# STM32L152 register map
File version: 1.2
CPU: CM3 r1p1, little endian, no MPU, no FPU, 4 interrupt priority bits
Registers are 32-bit, read-write, reset 0x0 unless marked. A register's access mark holds for its fields unless they carry their own. Offsets are from the block's base; [hi:lo] are bit positions; {n}, {i} and the like mark numbered series.

## RCC — Reset and clock control
Base 0x40023800
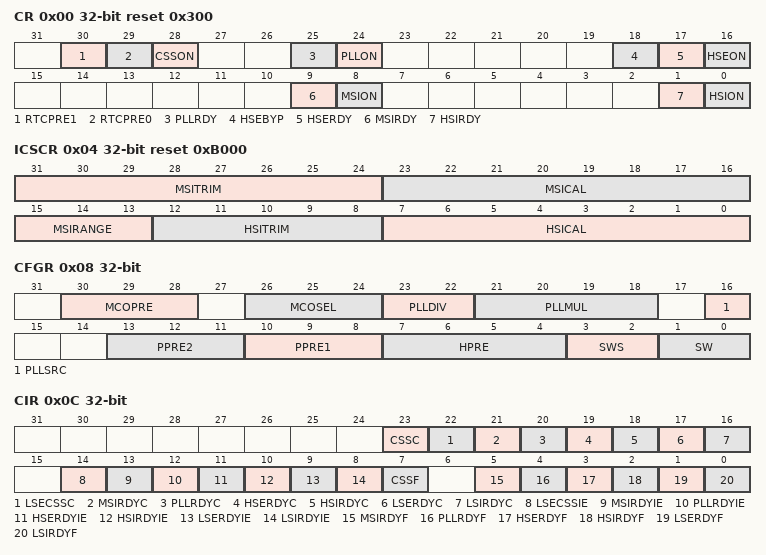
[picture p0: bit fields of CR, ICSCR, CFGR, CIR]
0x00 CR access per field reset 0x300 — Clock control register
  [30] RTCPRE1 rw — TC/LCD prescaler
  [29] RTCPRE0 rw
  [28] CSSON rw — Clock security system enable
  [25] PLLRDY ro — PLL clock ready flag
  [24] PLLON rw — PLL enable
  [18] HSEBYP rw — HSE clock bypass
  [17] HSERDY ro — HSE clock ready flag
  [16] HSEON rw — HSE clock enable
  [9] MSIRDY ro — MSI clock ready flag
  [8] MSION rw — MSI clock enable
  [1] HSIRDY ro — Internal high-speed clock ready flag
  [0] HSION rw — Internal high-speed clock enable
0x04 ICSCR access per field reset 0xB000 — Internal clock sources calibration register
  [31:24] MSITRIM rw — MSI clock trimming
  [23:16] MSICAL ro — MSI clock calibration
  [15:13] MSIRANGE rw — MSI clock ranges
  [12:8] HSITRIM rw — High speed internal clock trimming
  [7:0] HSICAL ro — nternal high speed clock calibration
0x08 CFGR access per field — Clock configuration register
  [30:28] MCOPRE rw — Microcontroller clock output prescaler
  [26:24] MCOSEL rw — Microcontroller clock output selection
  [23:22] PLLDIV rw — PLL output division
  [21:18] PLLMUL rw — PLL multiplication factor
  [16] PLLSRC rw — PLL entry clock source
  [13:11] PPRE2 rw — APB high-speed prescaler (APB2)
  [10:8] PPRE1 rw — APB low-speed prescaler (APB1)
  [7:4] HPRE rw — AHB prescaler
  [3:2] SWS ro — System clock switch status
  [1:0] SW rw — System clock switch
0x0C CIR access per field — Clock interrupt register
  [23] CSSC wo — Clock security system interrupt clear
  [22] LSECSSC wo — LSE CSS interrupt clear
  [21] MSIRDYC wo — MSI ready interrupt clear
  [20] PLLRDYC wo — PLL ready interrupt clear
  [19] HSERDYC wo — HSE ready interrupt clear
  [18] HSIRDYC wo — HSI ready interrupt clear
  [17] LSERDYC wo — LSE ready interrupt clear
  [16] LSIRDYC wo — LSI ready interrupt clear
  [14] LSECSSIE rw — LSE CSS interrupt enable
  [13] MSIRDYIE rw — MSI ready interrupt enable
  [12] PLLRDYIE rw — PLL ready interrupt enable
  [11] HSERDYIE rw — HSE ready interrupt enable
  [10] HSIRDYIE rw — HSI ready interrupt enable
  [9] LSERDYIE rw — LSE ready interrupt enable
  [8] LSIRDYIE rw — LSI ready interrupt enable
  [7] CSSF ro — Clock security system interrupt flag
  [5] MSIRDYF ro — MSI ready interrupt flag
  [4] PLLRDYF ro — PLL ready interrupt flag
  [3] HSERDYF ro — HSE ready interrupt flag
  [2] HSIRDYF ro — HSI ready interrupt flag
  [1] LSERDYF ro — LSE ready interrupt flag
  [0] LSIRDYF ro — LSI ready interrupt flag
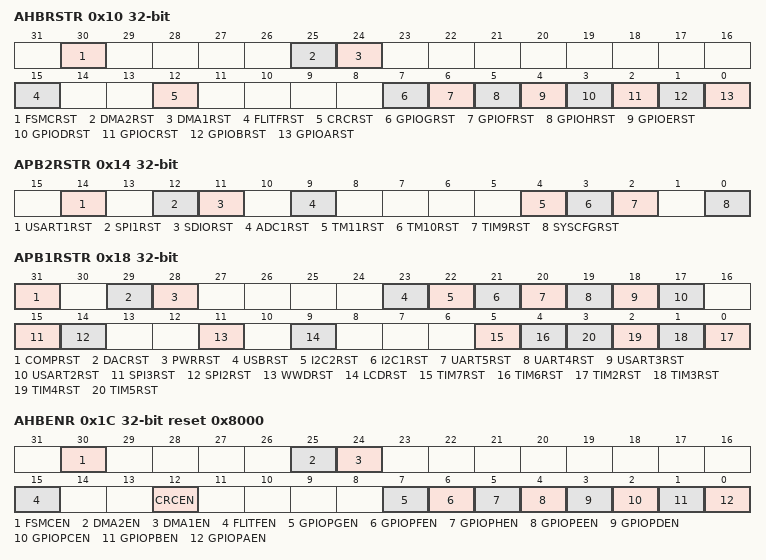
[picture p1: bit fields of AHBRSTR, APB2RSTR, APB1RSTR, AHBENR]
0x10 AHBRSTR — AHB peripheral reset register
  [30] FSMCRST — FSMC reset
  [25] DMA2RST — DMA2 reset
  [24] DMA1RST — DMA1 reset
  [15] FLITFRST — FLITF reset
  [12] CRCRST — CRC reset
  [7] GPIOGRST — IO port G reset
  [6] GPIOFRST — IO port F reset
  [5] GPIOHRST — IO port H reset
  [4] GPIOERST — IO port E reset
  [3] GPIODRST — IO port D reset
  [2] GPIOCRST — IO port C reset
  [1] GPIOBRST — IO port B reset
  [0] GPIOARST — IO port A reset
0x14 APB2RSTR — APB2 peripheral reset register
  [14] USART1RST, [12] SPI1RST, [11] SDIORST, [9] ADC1RST, [4] TM11RST, [3] TM10RST, [2] TIM9RST, [0] SYSCFGRST
0x18 APB1RSTR — APB1 peripheral reset register
  [31] COMPRST — COMP interface reset
  [29] DACRST — DAC interface reset
  [28] PWRRST — Power interface reset
  [23] USBRST — USB reset
  [22] I2C2RST — I2C 2 reset
  [21] I2C1RST — I2C 1 reset
  [20] UART5RST — UART 5 reset
  [19] UART4RST — UART 4 reset
  [18] USART3RST — USART 3 reset
  [17] USART2RST — USART 2 reset
  [15] SPI3RST — SPI 3 reset
  [14] SPI2RST — SPI 2 reset
  [11] WWDRST — Window watchdog reset
  [9] LCDRST — LCD reset
  [5] TIM7RST — Timer 7 reset
  [4] TIM6RST — Timer 6reset
  [n-2] TIM{n}RST (n=2..5) — Timer {n} reset
0x1C AHBENR reset 0x8000 — AHB peripheral clock enable register
  [30] FSMCEN
  [25] DMA2EN — DMA2 clock enable
  [24] DMA1EN — DMA1 clock enable
  [15] FLITFEN — FLITF clock enable
  [12] CRCEN — CRC clock enable
  [7] GPIOPGEN — IO port G clock enable
  [6] GPIOPFEN — IO port F clock enable
  [5] GPIOPHEN — IO port H clock enable
  [4] GPIOPEEN — IO port E clock enable
  [3] GPIOPDEN — IO port D clock enable
  [2] GPIOPCEN — IO port C clock enable
  [1] GPIOPBEN — IO port B clock enable
  [0] GPIOPAEN — IO port A clock enable
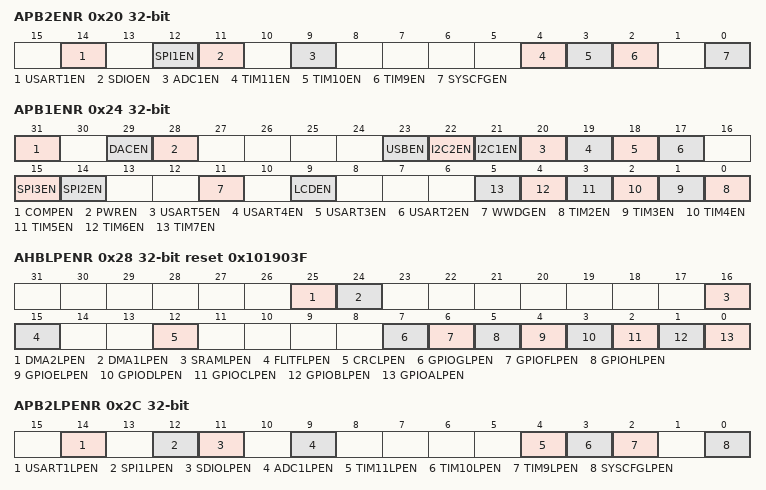
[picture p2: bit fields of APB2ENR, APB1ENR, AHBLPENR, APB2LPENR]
0x20 APB2ENR — APB2 peripheral clock enable register
  [14] USART1EN — USART1 clock enable
  [12] SPI1EN — SPI 1 clock enable
  [11] SDIOEN — SDIO clock enable
  [9] ADC1EN — ADC1 interface clock enable
  [4] TIM11EN — TIM11 timer clock enable
  [3] TIM10EN — TIM10 timer clock enable
  [2] TIM9EN — TIM9 timer clock enable
  [0] SYSCFGEN — System configuration controller clock enable
0x24 APB1ENR — APB1 peripheral clock enable register
  [31] COMPEN — COMP interface clock enable
  [29] DACEN — DAC interface clock enable
  [28] PWREN — Power interface clock enable
  [23] USBEN — USB clock enable
  [22] I2C2EN — I2C 2 clock enable
  [21] I2C1EN — I2C 1 clock enable
  [20] USART5EN — UART 5 clock enable
  [19] USART4EN — UART 4 clock enable
  [18] USART3EN — USART 3 clock enable
  [17] USART2EN — USART 2 clock enable
  [15] SPI3EN — SPI 3 clock enable
  [14] SPI2EN — SPI 2 clock enable
  [11] WWDGEN — Window watchdog clock enable
  [9] LCDEN — LCD clock enable
  [n-2] TIM{n}EN (n=2..7) — Timer {n} clock enable
0x28 AHBLPENR reset 0x101903F — AHB peripheral clock enable in low power mode register
  [25] DMA2LPEN — DMA2 clock enable during Sleep mode
  [24] DMA1LPEN — DMA1 clock enable during Sleep mode
  [16] SRAMLPEN — SRAM clock enable during Sleep mode
  [15] FLITFLPEN — FLITF clock enable during Sleep mode
  [12] CRCLPEN — CRC clock enable during Sleep mode
  [7] GPIOGLPEN — IO port G clock enable during Sleep mode
  [6] GPIOFLPEN — IO port F clock enable during Sleep mode
  [5] GPIOHLPEN — IO port H clock enable during Sleep mode
  [4] GPIOELPEN — IO port E clock enable during Sleep mode
  [3] GPIODLPEN — IO port D clock enable during Sleep mode
  [2] GPIOCLPEN — IO port C clock enable during Sleep mode
  [1] GPIOBLPEN — IO port B clock enable during Sleep mode
  [0] GPIOALPEN — IO port A clock enable during Sleep mode
0x2C APB2LPENR — APB2 peripheral clock enable in low power mode register
  [14] USART1LPEN — USART1 clock enable during Sleep mode
  [12] SPI1LPEN — SPI 1 clock enable during Sleep mode
  [11] SDIOLPEN — SDIO clock enable during Sleep mode
  [9] ADC1LPEN — ADC1 interface clock enable during Sleep mode
  [4] TIM11LPEN — TIM11 timer clock enable during Sleep mode
  [3] TIM10LPEN — TIM10 timer clock enable during Sleep mode
  [2] TIM9LPEN — TIM9 timer clock enable during Sleep mode
  [0] SYSCFGLPEN — System configuration controller clock enable during Sleep mode
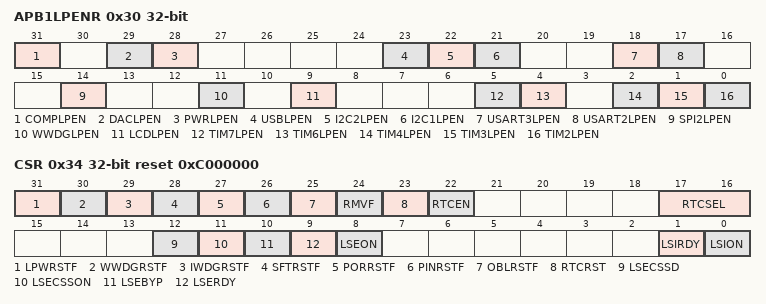
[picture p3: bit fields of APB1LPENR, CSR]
0x30 APB1LPENR — APB1 peripheral clock enable in low power mode register
  [31] COMPLPEN — COMP interface clock enable during Sleep mode
  [29] DACLPEN — DAC interface clock enable during Sleep mode
  [28] PWRLPEN — Power interface clock enable during Sleep mode
  [23] USBLPEN — USB clock enable during Sleep mode
  [22] I2C2LPEN — I2C 2 clock enable during Sleep mode
  [21] I2C1LPEN — I2C 1 clock enable during Sleep mode
  [18] USART3LPEN — USART 3 clock enable during Sleep mode
  [17] USART2LPEN — USART 2 clock enable during Sleep mode
  [14] SPI2LPEN — SPI 2 clock enable during Sleep mode
  [11] WWDGLPEN — Window watchdog clock enable during Sleep mode
  [9] LCDLPEN — LCD clock enable during Sleep mode
  [5] TIM7LPEN — Timer 7 clock enable during Sleep mode
  [4] TIM6LPEN — Timer 6 clock enable during Sleep mode
  [2] TIM4LPEN — Timer 4 clock enable during Sleep mode
  [1] TIM3LPEN — Timer 3 clock enable during Sleep mode
  [0] TIM2LPEN — Timer 2 clock enable during Sleep mode
0x34 CSR access per field reset 0xC000000 — Control/status register
  [31] LPWRSTF rw — Low-power reset flag
  [30] WWDGRSTF rw — Window watchdog reset flag
  [29] IWDGRSTF rw — Independent watchdog reset flag
  [28] SFTRSTF rw — Software reset flag
  [27] PORRSTF rw — POR/PDR reset flag
  [26] PINRSTF rw — PIN reset flag
  [25] OBLRSTF rw — Options bytes loading reset flag
  [24] RMVF rw — Remove reset flag
  [23] RTCRST rw — RTC software reset
  [22] RTCEN rw — RTC clock enable
  [17:16] RTCSEL rw — RTC and LCD clock source selection
  [12] LSECSSD rw — CSS on LSE failure Detection
  [11] LSECSSON rw — CSS on LSE enable
  [10] LSEBYP rw — External low-speed oscillator bypass
  [9] LSERDY ro — External low-speed oscillator ready
  [8] LSEON rw — External low-speed oscillator enable
  [1] LSIRDY ro — Internal low-speed oscillator ready
  [0] LSION rw — Internal low-speed oscillator enable
